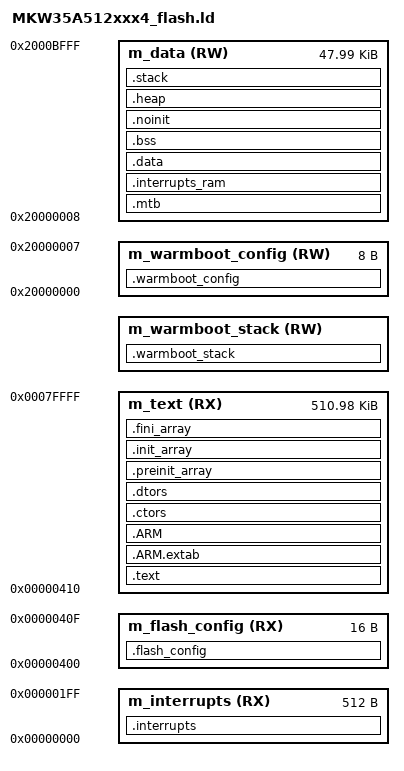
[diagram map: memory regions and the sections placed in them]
/*
** ###################################################################
**     Processors:          MKW35A512VFP4
**                          MKW35A512VFT4
**
**     Compiler:            GNU C Compiler
**     Reference manual:    MKW36A512RM Rev. 7, 07/2019
**     Version:             rev. 1.4, 2019-01-25
**     Build:               b190125
**
**     Abstract:
**         Linker file for the GNU C Compiler
**
**     Copyright 2016 Freescale Semiconductor, Inc.
**     Copyright 2016-2019 NXP
**     All rights reserved.
**
**     SPDX-License-Identifier: BSD-3-Clause
**
**     http:                 www.nxp.com
**     mail:                 support@nxp.com
**
** ###################################################################
*/

/* Entry Point */
ENTRY(Reset_Handler)

HEAP_SIZE  = DEFINED(__heap_size__)  ? __heap_size__  : 0x0400;
STACK_SIZE = DEFINED(__stack_size__) ? __stack_size__ : 0x0400;
M_VECTOR_RAM_SIZE = DEFINED(__ram_vector_table__) ? 0x0200 : 0x0;
WARMBOOT_STACK_ADDR = DEFINED(__warmboot_stack_addr__)  ? __warmboot_stack_addr__ : 0x1FFFC000;
WARMBOOT_STACK_SIZE = DEFINED(__warmboot_stack_size__)  ? __warmboot_stack_size__ : 0x00000400;

/* Specify the memory areas */
MEMORY
{
  m_interrupts          (RX)  : ORIGIN = 0x00000000, LENGTH = 0x00000200
  m_flash_config        (RX)  : ORIGIN = 0x00000400, LENGTH = 0x00000010
  m_text                (RX)  : ORIGIN = 0x00000410, LENGTH = 0x0007FBF0
  m_warmboot_stack      (RW)  : ORIGIN = WARMBOOT_STACK_ADDR, LENGTH = WARMBOOT_STACK_SIZE
  m_warmboot_config     (RW)  : ORIGIN = 0x20000000, LENGTH = 0x00000008
  m_data                (RW)  : ORIGIN = 0x20000008, LENGTH = 0x0000BFF8
}

/* Define output sections */
SECTIONS
{
  /* The startup code goes first into internal flash */
  .interrupts :
  {
    __VECTOR_TABLE = .;
    . = ALIGN(4);
    KEEP(*(.isr_vector))     /* Startup code */
    . = ALIGN(4);
  } > m_interrupts

  .flash_config :
  {
    . = ALIGN(4);
    KEEP(*(.FlashConfig))    /* Flash Configuration Field (FCF) */
    . = ALIGN(4);
  } > m_flash_config

  /* The program code and other data goes into internal flash */
  .text :
  {
    . = ALIGN(4);
    *(.text)                 /* .text sections (code) */
    *(.text*)                /* .text* sections (code) */
    *(.rodata)               /* .rodata sections (constants, strings, etc.) */
    *(.rodata*)              /* .rodata* sections (constants, strings, etc.) */
    *(.glue_7)               /* glue arm to thumb code */
    *(.glue_7t)              /* glue thumb to arm code */
    *(.eh_frame)
    KEEP (*(.init))
    KEEP (*(.fini))
    . = ALIGN(4);
  } > m_text

  .ARM.extab :
  {
    *(.ARM.extab* .gnu.linkonce.armextab.*)
  } > m_text

  .ARM :
  {
    __exidx_start = .;
    *(.ARM.exidx*)
    __exidx_end = .;
  } > m_text

 .ctors :
  {
    __CTOR_LIST__ = .;
    /* gcc uses crtbegin.o to find the start of
       the constructors, so we make sure it is
       first.  Because this is a wildcard, it
       doesn't matter if the user does not
       actually link against crtbegin.o; the
       linker won't look for a file to match a
       wildcard.  The wildcard also means that it
       doesn't matter which directory crtbegin.o
       is in.  */
    KEEP (*crtbegin.o(.ctors))
    KEEP (*crtbegin?.o(.ctors))
    /* We don't want to include the .ctor section from
       from the crtend.o file until after the sorted ctors.
       The .ctor section from the crtend file contains the
       end of ctors marker and it must be last */
    KEEP (*(EXCLUDE_FILE(*crtend?.o *crtend.o) .ctors))
    KEEP (*(SORT(.ctors.*)))
    KEEP (*(.ctors))
    __CTOR_END__ = .;
  } > m_text

  .dtors :
  {
    __DTOR_LIST__ = .;
    KEEP (*crtbegin.o(.dtors))
    KEEP (*crtbegin?.o(.dtors))
    KEEP (*(EXCLUDE_FILE(*crtend?.o *crtend.o) .dtors))
    KEEP (*(SORT(.dtors.*)))
    KEEP (*(.dtors))
    __DTOR_END__ = .;
  } > m_text

  .preinit_array :
  {
    PROVIDE_HIDDEN (__preinit_array_start = .);
    KEEP (*(.preinit_array*))
    PROVIDE_HIDDEN (__preinit_array_end = .);
  } > m_text

  .init_array :
  {
    PROVIDE_HIDDEN (__init_array_start = .);
    KEEP (*(SORT(.init_array.*)))
    KEEP (*(.init_array*))
    PROVIDE_HIDDEN (__init_array_end = .);
  } > m_text

  .fini_array :
  {
    PROVIDE_HIDDEN (__fini_array_start = .);
    KEEP (*(SORT(.fini_array.*)))
    KEEP (*(.fini_array*))
    PROVIDE_HIDDEN (__fini_array_end = .);
  } > m_text

  __etext = .;    /* define a global symbol at end of code */
  __DATA_ROM = .; /* Symbol is used by startup for data initialization */

  /* reserve MTB memory at the beginning of m_data */
  .mtb : /* MTB buffer address as defined by the hardware */
  {
    . = ALIGN(8);
    _mtb_start = .;
    KEEP(*(.mtb_buf)) /* need to KEEP Micro Trace Buffer as not referenced by application */
    . = ALIGN(8);
    _mtb_end = .;
  } > m_data

  .interrupts_ram :
  {
    . = ALIGN(4);
    __VECTOR_RAM__ = .;
    __interrupts_ram_start__ = .; /* Create a global symbol at data start */
    *(.m_interrupts_ram)     /* This is a user defined section */
    . += M_VECTOR_RAM_SIZE;
    . = ALIGN(4);
    __interrupts_ram_end__ = .; /* Define a global symbol at data end */
  } > m_data

  __VECTOR_RAM = DEFINED(__ram_vector_table__) ? __VECTOR_RAM__ : ORIGIN(m_interrupts);
  __RAM_VECTOR_TABLE_SIZE_BYTES = DEFINED(__ram_vector_table__) ? (__interrupts_ram_end__ - __interrupts_ram_start__) : 0x0;

  .warmboot_stack :
  {
    . = ALIGN(8);
    __WarmbootStackBase = .;
    . += WARMBOOT_STACK_SIZE;
    __WarmbootStackLimit = .;
  } > m_warmboot_stack

  .warmboot_config : AT(__DATA_ROM)
  {
    . = ALIGN(4);
    __warmboot_config_start__ = .;
    *(WarmbootConfig)
    . = ALIGN(4);
    __warmboot_config_end__ = .;
  } > m_warmboot_config

  __WARMBOOT_CONFIG_END = __DATA_ROM + (__warmboot_config_end__ - __warmboot_config_start__);

  .data : AT(__WARMBOOT_CONFIG_END)
  {
    . = ALIGN(4);
    __DATA_RAM = .;
    __data_start__ = .;      /* create a global symbol at data start */
    *(.data)                 /* .data sections */
    *(.data*)                /* .data* sections */
    KEEP(*(.jcr*))
    . = ALIGN(4);
    __data_end__ = .;        /* define a global symbol at data end */
  } > m_data

  __DATA_END = __WARMBOOT_CONFIG_END + (__data_end__ - __data_start__);
  text_end = ORIGIN(m_text) + LENGTH(m_text);
  ASSERT(__DATA_END <= text_end, "region m_text overflowed with text and data")

  /* Uninitialized data section */
  .bss :
  {
    /* This is used by the startup in order to initialize the .bss section */
    . = ALIGN(4);
    __START_BSS = .;
    __bss_start__ = .;
    *(.bss)
    *(.bss*)
    *(COMMON)
    . = ALIGN(4);
    __bss_end__ = .;
    __END_BSS = .;
  } > m_data

  .noinit :
  {
    /* Data section which will not be initialized */
    . = ALIGN(4);
    __noinit_start__ = .;
    *(NOINIT)
    . = ALIGN(4);
    __noinit_end__ = .;
  } > m_data

  .heap :
  {
    . = ALIGN(8);
    __end__ = .;
    PROVIDE(end = .);
    __HeapBase = .;
    . += HEAP_SIZE;
    __HeapLimit = .;
    __heap_limit = .; /* Add for _sbrk */
  } > m_data

  .stack :
  {
    . = ALIGN(8);
    . += STACK_SIZE;
  } > m_data

  /* Initializes stack on the end of block */
  __StackTop   = ORIGIN(m_data) + LENGTH(m_data);
  __StackLimit = __StackTop - STACK_SIZE;
  PROVIDE(__stack = __StackTop);

  .ARM.attributes 0 : { *(.ARM.attributes) }

  ASSERT(__StackLimit >= __HeapLimit, "region m_data overflowed with stack and heap")
}

